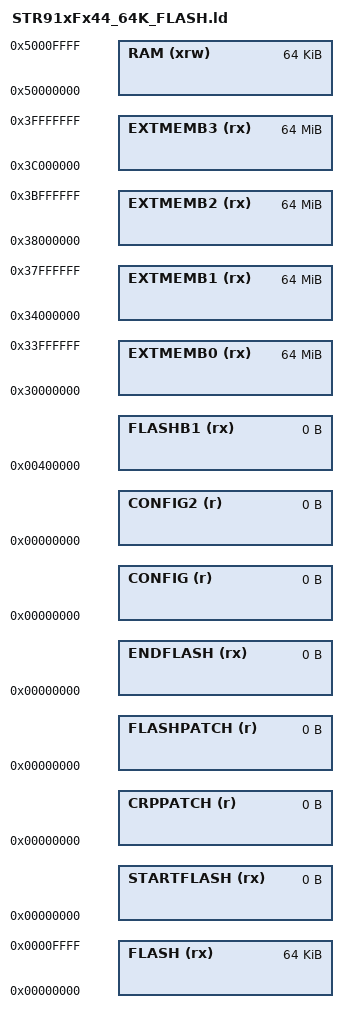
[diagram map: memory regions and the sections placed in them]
/*
Default secondary/main linker script for STR91xFx44
Copyright RAISONANCE S.A.S. 2007-2015

!!! This file is automatically generated by Ride if the default linker script option is active !!!

Do not modify it if the option is set, as it will be erased at every link.
If you need to use your own script please configure your Ride7 project linker options to use your custom linker script
You can take this one as example for wrting your custom linker script
You can use, copy and distribute this file freely, but without any waranty.*/



/* this tells the sub-scripts that the Starter Kit Limited linker option is active */
___SK_limit___ = 1 ;

/* include the common STRxxx sub-script */
INCLUDE "STR91x_COMMON.ld"


/*********** BEGIN SUBSCRIPT ************/

/*
Linker subscript for STR91xFxxx definitions
Copyright RAISONANCE 2006
You can use, modify and distribute this file freely, but without any warranty.
*/


/* Memory Spaces Definitions */

MEMORY
{
  FLASH (rx) : ORIGIN = 0, LENGTH = 64K
  FLASHB1 (rx) : ORIGIN = 0x00400000, LENGTH = 0
  STARTFLASH (rx) : ORIGIN = 0x0, LENGTH = 0x0
  CRPPATCH (r) : ORIGIN = 0x0, LENGTH = 0
  FLASHPATCH (r) : ORIGIN = 0x00000000, LENGTH = 0
  ENDFLASH (rx)  : ORIGIN = 0x00000000, LENGTH = 0
  EXTMEMB0 (rx) : ORIGIN = 0x30000000, LENGTH = 64M
  EXTMEMB1 (rx) : ORIGIN = 0x34000000, LENGTH = 64M
  EXTMEMB2 (rx) : ORIGIN = 0x38000000, LENGTH = 64M
  EXTMEMB3 (rx) : ORIGIN = 0x3C000000, LENGTH = 64M
  RAM (xrw) : ORIGIN = 0x50000000, LENGTH = 64K
  CONFIG   (r)    : ORIGIN = 0x00000000, LENGTH = 0x0
  CONFIG2  (r)    : ORIGIN = 0x00000000, LENGTH = 0x0
}

/* higher address of the user mode stack */
_estack = 0x50018000;

PROVIDE (  _bb_size = 0x1 ) ;
PROVIDE ( _nbb_size = 0x3 ) ;
PROVIDE ( _nbb_addr = 0x00100000 ) ;

/************ END SUBSCRIPT *************/

/* include the sections management sub-script for FLASH mode */
INCLUDE "sections_FLASH.ld"
